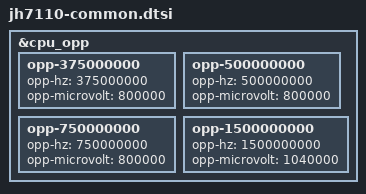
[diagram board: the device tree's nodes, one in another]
// SPDX-License-Identifier: GPL-2.0 OR MIT
/*
 * Copyright (C) 2022 StarFive Technology Co., Ltd.
 * Copyright (C) 2022 Emil Renner Berthing <kernel@esmil.dk>
 */

/dts-v1/;
#include "jh711x-common.dtsi"

&cpu_opp {
	opp-375000000 {
		opp-hz = /bits/ 64 <375000000>;
		opp-microvolt = <800000>;
	};
	opp-500000000 {
		opp-hz = /bits/ 64 <500000000>;
		opp-microvolt = <800000>;
	};
	opp-750000000 {
		opp-hz = /bits/ 64 <750000000>;
		opp-microvolt = <800000>;
	};
	opp-1500000000 {
		opp-hz = /bits/ 64 <1500000000>;
		opp-microvolt = <1040000>;
	};
};
